VERSION "Emergency_System_CAN_Powertrain_v1.3"

NS_ :

BS_:

BU_: SIL_TEST_CTRL ENGINE_CTRL TRANSMISSION_CTRL DOMAIN_GW_ROUTER Vector__XXX

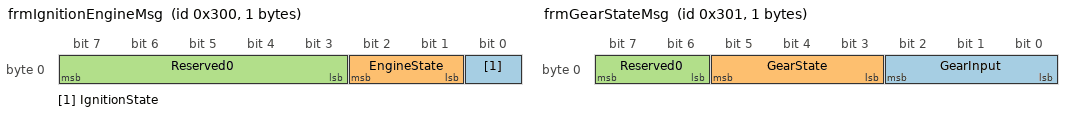
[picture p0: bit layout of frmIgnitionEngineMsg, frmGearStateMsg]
BO_ 768 frmIgnitionEngineMsg: 1 SIL_TEST_CTRL
 SG_ IgnitionState  : 0|1@1+ (1,0) [0|1] "" ENGINE_CTRL
 SG_ EngineState    : 1|2@1+ (1,0) [0|3] "" ENGINE_CTRL
 SG_ Reserved0      : 3|5@1+ (1,0) [0|0] "" Vector__XXX

BO_ 769 frmGearStateMsg: 1 SIL_TEST_CTRL
 SG_ GearInput      : 0|3@1+ (1,0) [0|7] "" TRANSMISSION_CTRL
 SG_ GearState      : 3|3@1+ (1,0) [0|7] "" TRANSMISSION_CTRL
 SG_ Reserved0      : 6|2@1+ (1,0) [0|0] "" Vector__XXX

BO_ 770 frmPowertrainGatewayMsg: 2 DOMAIN_GW_ROUTER
 SG_ RoutingPolicy  : 0|8@1+ (1,0) [0|255] "" ENGINE_CTRL,TRANSMISSION_CTRL
 SG_ BoundaryStatus : 8|8@1+ (1,0) [0|255] "" ENGINE_CTRL,TRANSMISSION_CTRL

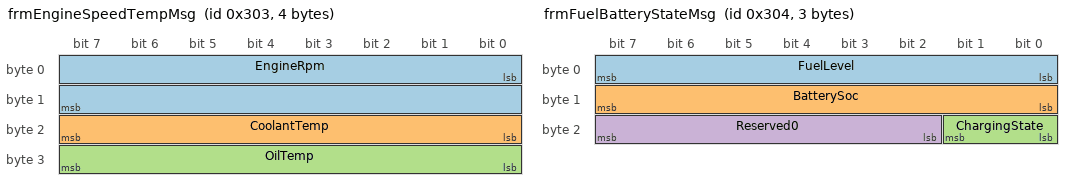
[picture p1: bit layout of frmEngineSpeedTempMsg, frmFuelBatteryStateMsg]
BO_ 771 frmEngineSpeedTempMsg: 4 ENGINE_CTRL
 SG_ EngineRpm       : 0|16@1+ (1,0) [0|65535] "rpm" TRANSMISSION_CTRL,DOMAIN_GW_ROUTER
 SG_ CoolantTemp     : 16|8@1+ (1,0) [0|255] "degC" TRANSMISSION_CTRL,DOMAIN_GW_ROUTER
 SG_ OilTemp         : 24|8@1+ (1,0) [0|255] "degC" TRANSMISSION_CTRL,DOMAIN_GW_ROUTER

BO_ 772 frmFuelBatteryStateMsg: 3 ENGINE_CTRL
 SG_ FuelLevel       : 0|8@1+ (1,0) [0|100] "%" DOMAIN_GW_ROUTER
 SG_ BatterySoc      : 8|8@1+ (1,0) [0|100] "%" DOMAIN_GW_ROUTER
 SG_ ChargingState   : 16|2@1+ (1,0) [0|3] "" DOMAIN_GW_ROUTER
 SG_ Reserved0       : 18|6@1+ (1,0) [0|0] "" Vector__XXX

BO_ 773 frmThrottleStateMsg: 2 ENGINE_CTRL
 SG_ ThrottlePos     : 0|8@1+ (1,0) [0|100] "%" TRANSMISSION_CTRL,DOMAIN_GW_ROUTER
 SG_ ThrottleReq     : 8|8@1+ (1,0) [0|100] "%" TRANSMISSION_CTRL,DOMAIN_GW_ROUTER

BO_ 774 frmTransmissionTempMsg: 2 TRANSMISSION_CTRL
 SG_ TransOilTemp    : 0|8@1+ (1,0) [0|255] "degC" ENGINE_CTRL,DOMAIN_GW_ROUTER
 SG_ ClutchTemp      : 8|8@1+ (1,0) [0|255] "degC" ENGINE_CTRL,DOMAIN_GW_ROUTER

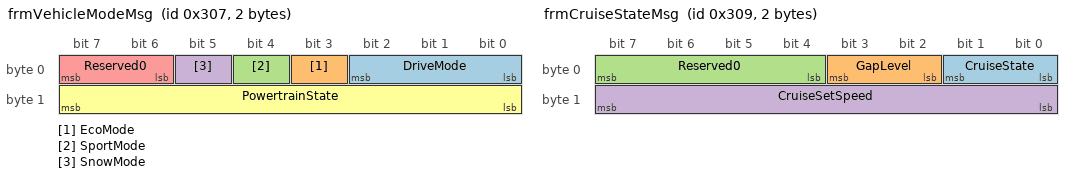
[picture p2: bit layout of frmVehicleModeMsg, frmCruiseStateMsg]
BO_ 775 frmVehicleModeMsg: 2 DOMAIN_GW_ROUTER
 SG_ DriveMode       : 0|3@1+ (1,0) [0|7] "" ENGINE_CTRL,TRANSMISSION_CTRL
 SG_ EcoMode         : 3|1@1+ (1,0) [0|1] "" ENGINE_CTRL,TRANSMISSION_CTRL
 SG_ SportMode       : 4|1@1+ (1,0) [0|1] "" ENGINE_CTRL,TRANSMISSION_CTRL
 SG_ SnowMode        : 5|1@1+ (1,0) [0|1] "" ENGINE_CTRL,TRANSMISSION_CTRL
 SG_ Reserved0       : 6|2@1+ (1,0) [0|0] "" Vector__XXX
 SG_ PowertrainState : 8|8@1+ (1,0) [0|255] "" ENGINE_CTRL,TRANSMISSION_CTRL

BO_ 776 frmPowerLimitMsg: 2 DOMAIN_GW_ROUTER
 SG_ TorqueLimit     : 0|8@1+ (1,0) [0|255] "Nm" ENGINE_CTRL,TRANSMISSION_CTRL
 SG_ SpeedLimit      : 8|8@1+ (1,0) [0|255] "km/h" ENGINE_CTRL,TRANSMISSION_CTRL

BO_ 777 frmCruiseStateMsg: 2 DOMAIN_GW_ROUTER
 SG_ CruiseState     : 0|2@1+ (1,0) [0|3] "" ENGINE_CTRL,TRANSMISSION_CTRL
 SG_ GapLevel        : 2|2@1+ (1,0) [0|3] "" ENGINE_CTRL,TRANSMISSION_CTRL
 SG_ Reserved0       : 4|4@1+ (1,0) [0|0] "" Vector__XXX
 SG_ CruiseSetSpeed  : 8|8@1+ (1,0) [0|255] "km/h" ENGINE_CTRL,TRANSMISSION_CTRL

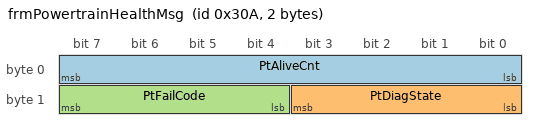
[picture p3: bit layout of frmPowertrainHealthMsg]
BO_ 778 frmPowertrainHealthMsg: 2 DOMAIN_GW_ROUTER
 SG_ PtAliveCnt      : 0|8@1+ (1,0) [0|255] "" SIL_TEST_CTRL
 SG_ PtDiagState     : 8|4@1+ (1,0) [0|15] "" SIL_TEST_CTRL
 SG_ PtFailCode      : 12|4@1+ (1,0) [0|15] "" SIL_TEST_CTRL

CM_ BU_ SIL_TEST_CTRL "SIL test controller (powertrain-domain CAN input reserved).";
CM_ BU_ ENGINE_CTRL "Vehicle baseline node for ignition and engine-state handling (Req_101).";
CM_ BU_ TRANSMISSION_CTRL "Vehicle baseline node for gear-state handling (Req_102).";
CM_ BU_ DOMAIN_GW_ROUTER "Domain gateway routing manager (Req_110).";
CM_ BU_ Vector__XXX "Reserved node for unused or filler signals.";

CM_ BO_ 768 "Powertrain baseline: ignition state and engine state.";
CM_ BO_ 769 "Powertrain baseline: gear input and gear state.";
CM_ BO_ 770 "Powertrain baseline: domain routing policy and boundary status.";
CM_ BO_ 771 "Powertrain baseline: engine RPM and thermal state.";
CM_ BO_ 772 "Powertrain baseline: fuel and battery state.";
CM_ BO_ 773 "Powertrain baseline: throttle position and request.";
CM_ BO_ 774 "Powertrain baseline: transmission thermal state.";
CM_ BO_ 775 "Powertrain baseline: drive mode and powertrain state.";
CM_ BO_ 776 "Powertrain baseline: torque and speed limits.";
CM_ BO_ 777 "Powertrain baseline: cruise state, gap, and set speed.";
CM_ BO_ 778 "Powertrain health/diagnostic state.";

CM_ "Domain split: powertrain CAN network from emergency_system.dbc baseline.";
CM_ "Post-mentoring expansion: baseline powertrain frames added for Req_101/Req_102/Req_110.";

BA_DEF_ BO_ "GenMsgCycleTime" INT 0 10000;
BA_DEF_DEF_ "GenMsgCycleTime" 0;

BA_ "GenMsgCycleTime" BO_ 768 100;
BA_ "GenMsgCycleTime" BO_ 769 100;
BA_ "GenMsgCycleTime" BO_ 770 100;
BA_ "GenMsgCycleTime" BO_ 771 100;
BA_ "GenMsgCycleTime" BO_ 772 100;
BA_ "GenMsgCycleTime" BO_ 773 100;
BA_ "GenMsgCycleTime" BO_ 774 100;
BA_ "GenMsgCycleTime" BO_ 775 100;
BA_ "GenMsgCycleTime" BO_ 776 100;
BA_ "GenMsgCycleTime" BO_ 777 100;
BA_ "GenMsgCycleTime" BO_ 778 100;

  0 "Off"
  1 "On" ;

  0 "Off"
  1 "Starting"
  2 "Running"
  3 "Fault" ;

  0 "P"
  1 "R"
  2 "N"
  3 "D"
  4 "S"
  5 "M"
  6 "Reserved6"
  7 "Reserved7" ;

  0 "P"
  1 "R"
  2 "N"
  3 "D"
  4 "S"
  5 "M"
  6 "Reserved6"
  7 "Reserved7" ;

  0 "Idle"
  1 "Charging"
  2 "Discharging"
  3 "Fault" ;

  0 "Normal"
  1 "Eco"
  2 "Sport"
  3 "Snow"
  4 "Comfort"
  5 "Custom"
  6 "Reserved6"
  7 "Reserved7" ;

  0 "Off"
  1 "On" ;

  0 "Off"
  1 "On" ;

  0 "Off"
  1 "On" ;

  0 "Off"
  1 "Standby"
  2 "Active"
  3 "Fault" ;
